# STM32H503xx register map
File version: 1.0
Registers are 32-bit, read-write, reset 0x0 unless marked. A register's access mark holds for its fields unless they carry their own. Offsets are from the block's base; [hi:lo] are bit positions; {n}, {i} and the like mark numbered series.

## ICACHE — Instruction Cache
Base 0x40030400
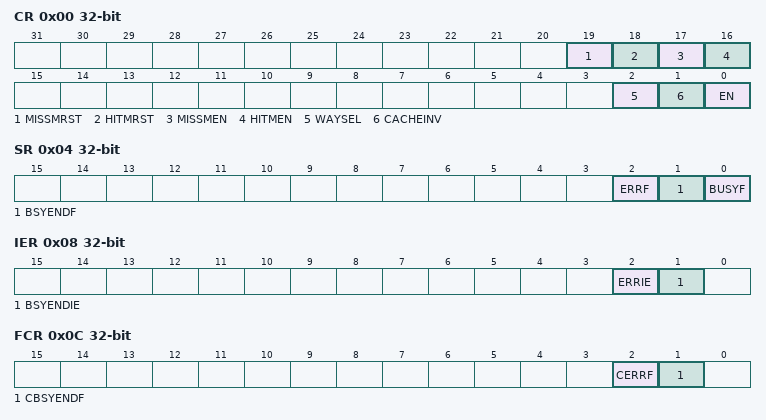
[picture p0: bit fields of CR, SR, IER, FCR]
0x00 CR — ICACHE control register
  [19] MISSMRST — Miss monitor reset
  [18] HITMRST — Hit monitor reset
  [17] MISSMEN — Miss monitor enable
  [16] HITMEN — Hit monitor enable
  [2] WAYSEL — Ways selection
    0=ICACHE_1WAY (1-way cache (direct mapped cache)); 1=ICACHE_2WAYS (2-ways set associative cache (default))
  [1] CACHEINV — Cache invalidation
  [0] EN — Enable
0x04 SR — ICACHE status register
  [2] ERRF — Cache error flag
  [1] BSYENDF — Busy end flag
  [0] BUSYF — Busy flag
0x08 IER — ICACHE interrupt enable register
  [2] ERRIE — Cache error interrupt enable
  [1] BSYENDIE — Busy end interrupt enable
0x0C FCR — ICACHE Flag clear register
  [2] CERRF — Cache error flag clear
  [1] CBSYENDF — Busy end flag clear
0x10 HMONR — ICACHE hit monitor register
  [31:0] HITMON — Cache hit monitor register
0x14 MMONR — ICACHE miss monitor register
  [15:0] MISSMON — Cache miss monitor register

## GTZC_TZSC1 — Global TrustZone Controller
Base 0x40032400
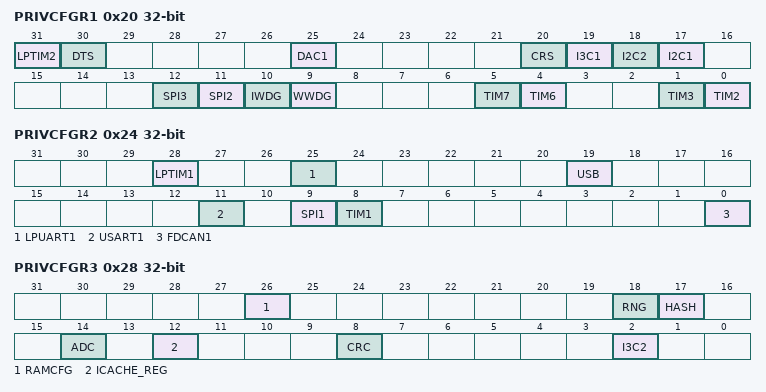
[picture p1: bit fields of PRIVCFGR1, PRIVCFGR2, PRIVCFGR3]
0x20 PRIVCFGR1 — TZSC privilege configuration register 1
  [31] LPTIM2, [30] DTS, [25] DAC1, [20] CRS, [19] I3C1, [18] I2C2, [17] I2C1, [12] SPI3, [11] SPI2, [10] IWDG, [9] WWDG, [5] TIM7, [4] TIM6, [1] TIM3, [0] TIM2
0x24 PRIVCFGR2 — TZSC privilege configuration register 2
  [28] LPTIM1, [25] LPUART1, [19] USB, [11] USART1, [9] SPI1, [8] TIM1, [0] FDCAN1
0x28 PRIVCFGR3 — TZSC privilege configuration register 3
  [26] RAMCFG, [18] RNG, [17] HASH, [14] ADC, [12] ICACHE_REG, [8] CRC, [2] I3C2
0x70 MPCWM4ACFGR — TZSC memory 4 sub-region A watermark configuration register
0x74 MPCWM4AR — TZSC memory 4 sub-region A watermark register

## GTZC_MPCBB1
Base 0x40032C00
Same registers: GTZC_MPCBB2 0x40033000
{0x200+4i} PRIVCFGR{i} (i=0..31) — MPCBBx privilege configuration registers

## GPIOA — General Purpose I/O
Base 0x42020000
Same registers: GPIOB 0x42020400, GPIOC 0x42020800, GPIOD 0x42020C00, GPIOH 0x42021C00
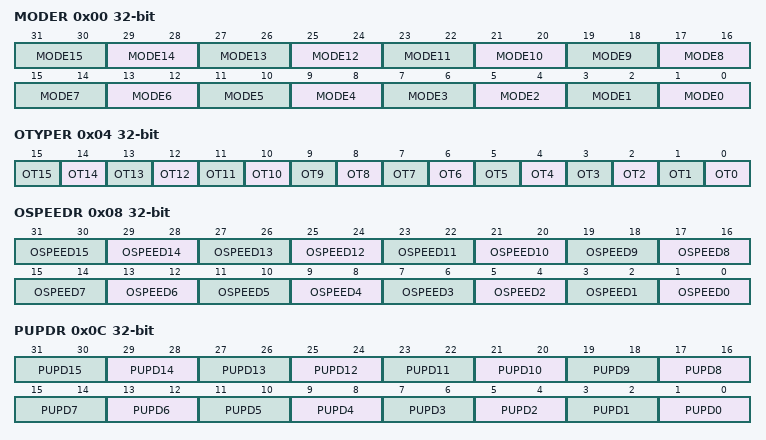
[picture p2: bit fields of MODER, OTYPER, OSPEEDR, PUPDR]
0x00 MODER — GPIO port mode register
  [2n+1:2n] MODE{n} (n=0..15)
0x04 OTYPER — GPIO port output type register
  [n] OT{n} (n=0..15)
0x08 OSPEEDR — GPIO port output speed register
  [2n+1:2n] OSPEED{n} (n=0..15)
0x0C PUPDR — GPIO port pull-up/pull-down register
  [2n+1:2n] PUPD{n} (n=0..15)
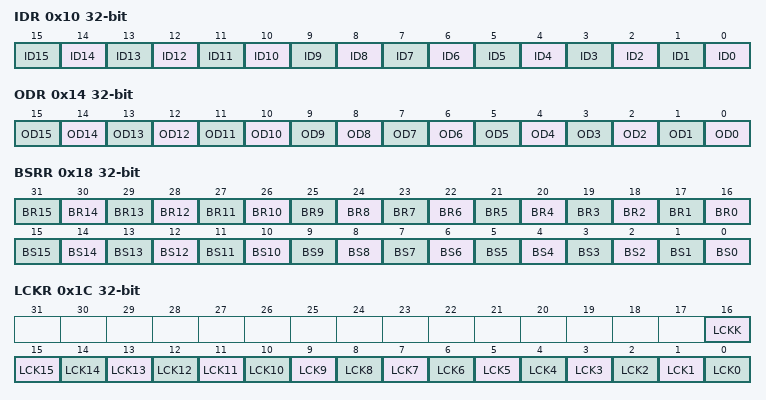
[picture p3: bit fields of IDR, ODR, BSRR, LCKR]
0x10 IDR — GPIO port input data register
  [n] ID{n} (n=0..15)
0x14 ODR — GPIO port output data register
  [n] OD{n} (n=0..15)
0x18 BSRR — GPIO port bit set/reset register
  [n+16] BR{n} (n=0..15), [n] BS{n} (n=0..15)
0x1C LCKR — GPIO port configuration lock register
  [16] LCKK, [n] LCK{n} (n=0..15)
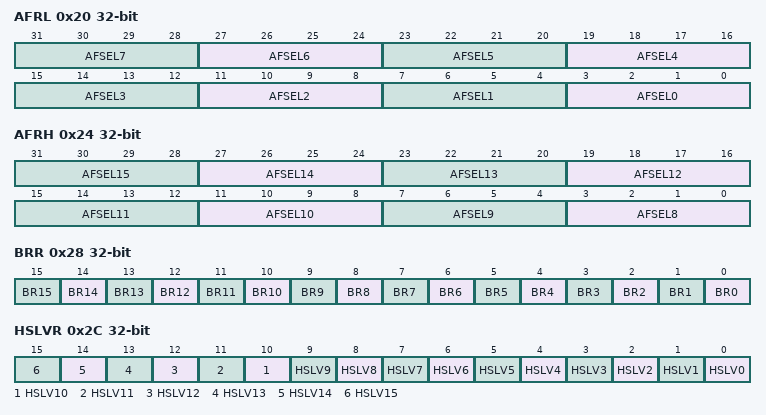
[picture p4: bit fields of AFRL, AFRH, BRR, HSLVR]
0x20 AFRL — GPIO alternate function registers
  [4n+3:4n] AFSEL{n} (n=0..7)
0x24 AFRH — GPIO alternate function registers
  [4n-29:4n-32] AFSEL{n} (n=8..15)
0x28 BRR — GPIO Bit Reset register
  [n] BR{n} (n=0..15)
0x2C HSLVR — GPIO high-speed low voltage register
  [n] HSLV{n} (n=0..15)
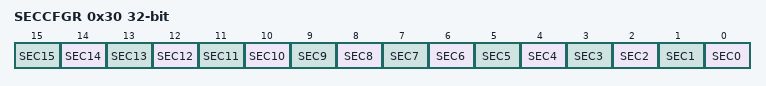
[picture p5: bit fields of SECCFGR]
0x30 SECCFGR — GPIO secure configuration register
  [n] SEC{n} (n=0..15)

## ADC12_COMMON
Base 0x42028300
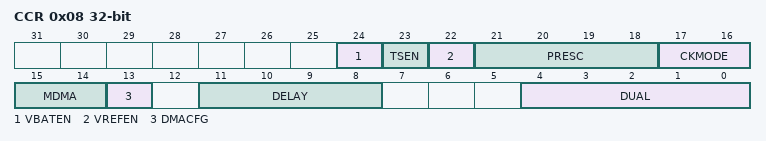
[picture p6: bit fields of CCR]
0x08 CCR — ADC common configuration register
  [24] VBATEN — ADC internal path to battery voltage enable
  [23] TSEN — ADC internal path to temperature sensor enable
  [22] VREFEN — ADC internal path to VrefInt enable
  [21:18] PRESC — ADC common clock prescaler, only for clock source asynchronous
  [17:16] CKMODE — ADC common clock source and prescaler (prescaler only for clock source synchronous)
  [15:14] MDMA — ADC multimode DMA transfer enable
  [13] DMACFG — ADC multimode DMA transfer configuration
  [11:8] DELAY — ADC multimode delay between 2 sampling phases
  [4:0] DUAL — ADC multimode mode selection

## HASH
Base 0x420C0400
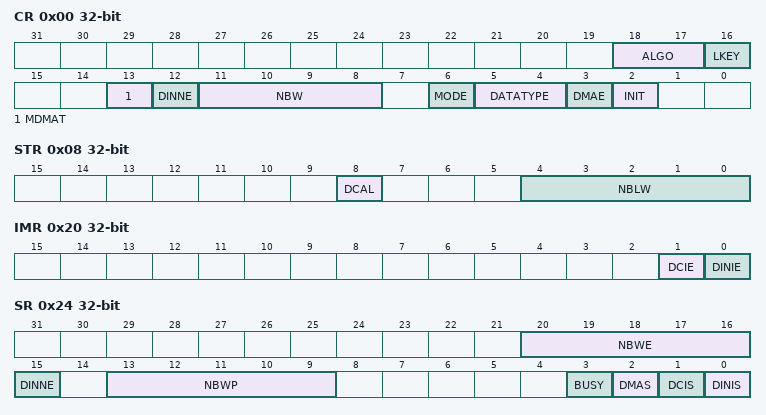
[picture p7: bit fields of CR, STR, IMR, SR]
0x00 CR — HASH control register
  [18:17] ALGO, [16] LKEY, [13] MDMAT, [12] DINNE, [11:8] NBW, [6] MODE, [5:4] DATATYPE, [3] DMAE, [2] INIT
0x04 DIN — HASH data input register
  [31:0] DATAIN
0x08 STR — HASH start register
  [8] DCAL, [4:0] NBLW
{0xC+4i} HRA{i} (i=0..4) — HASH digest registers
0x20 IMR — HASH interrupt enable register
  [1] DCIE, [0] DINIE
0x24 SR — HASH status register
  [20:16] NBWE, [15] DINNE, [13:9] NBWP, [3] BUSY, [2] DMAS, [1] DCIS, [0] DINIS
{0xF8+4i} CSR{i} (i=0..53) — HASH context swap registers
{0x310+4i} HR{i} (i=0..7) — HASH digest registers
